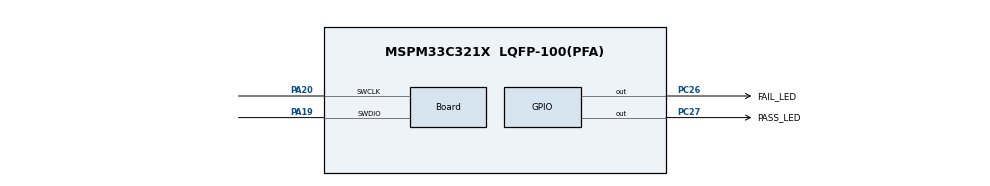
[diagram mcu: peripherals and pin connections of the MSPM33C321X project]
/**
 * @cliArgs --device "MSPM33C321X" --part "Default" --package "LQFP-100(PFA)" --product "mspm33_sdk@1.02.00.00"
 * @versions {"tool":"1.26.0+4407"}
 */
// @cliArgs --board /ti/boards/LP_MSPM33C321A --rtos nortos

/**
 * Import the modules used in this configuration.
 */
const AESADV        = scripting.addModule("/ti/driverlib/AESADV");
const Board         = scripting.addModule("/ti/driverlib/Board");
const GPIO          = scripting.addModule("/ti/driverlib/GPIO", {}, false);
const GPIO1         = GPIO.addInstance();
const NONMAIN       = scripting.addModule("/ti/driverlib/NONMAIN");
const SYSCTL        = scripting.addModule("/ti/driverlib/SYSCTL");
const ProjectConfig = scripting.addModule("/ti/project_config/ProjectConfig");

/**
 * Write custom configuration values to the imported modules.
 */
AESADV.enabledInterrupts = ["DL_AESADV_INTERRUPT_INPUT_CONTEXT_READY","DL_AESADV_INTERRUPT_INPUT_READY","DL_AESADV_INTERRUPT_OUTPUT_READY","DL_AESADV_INTERRUPT_SAVED_OUTPUT_CONTEXT_READY"];
AESADV.lowerCryptoLength = 0x3C;
AESADV.aadLength         = 0x14;
AESADV.mode              = "DL_AESADV_MODE_GCM_AUTONOMOUS";

Board.peripheral.$assign          = "DEBUGSS";
Board.peripheral.swclkPin.$assign = "PA20";
Board.peripheral.swdioPin.$assign = "PA19";

GPIO1.$name                               = "GPIO_LEDS";
GPIO1.associatedPins.create(2);
GPIO1.associatedPins[0].launchPadShortcut = "LED2GreenEn";
GPIO1.associatedPins[0].$name             = "PASS_LED";
GPIO1.associatedPins[0].pin.$assign       = "PC27";
GPIO1.associatedPins[1].$name             = "FAIL_LED";
GPIO1.associatedPins[1].launchPadShortcut = "LED2RedEn";
GPIO1.associatedPins[1].pin.$assign       = "PC26";

NONMAIN.nonmainWarning = true;
NONMAIN.cscExists      = true;

SYSCTL.peripheral.$assign = "SYSCTL";

ProjectConfig.migrationCondition = true;
ProjectConfig.genLinker          = false;
